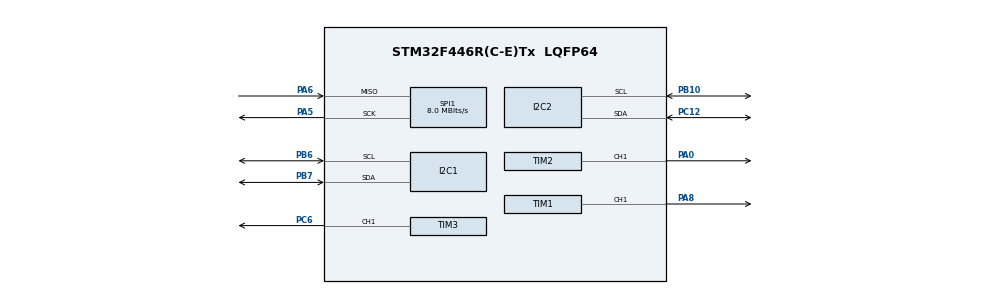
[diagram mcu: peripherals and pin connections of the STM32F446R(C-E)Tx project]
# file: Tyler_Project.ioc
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Mcu.Family=STM32F4
Mcu.Name=STM32F446R(C-E)Tx
Mcu.Package=LQFP64
NVIC.PriorityGroup=NVIC_PRIORITYGROUP_4
PA0-WKUP.Signal=S_TIM2_CH1_ETR
PA5.Mode=RX_Only_Simplex_Unidirect_Master
PA5.Signal=SPI1_SCK
PA6.Mode=RX_Only_Simplex_Unidirect_Master
PA6.Signal=SPI1_MISO
PA8.Signal=S_TIM1_CH1
PB10.Mode=I2C
PB10.Signal=I2C2_SCL
PB6.Mode=I2C
PB6.Signal=I2C1_SCL
PB7.Mode=I2C
PB7.Signal=I2C1_SDA
PC12.Mode=I2C
PC12.Signal=I2C2_SDA
PC6.Signal=S_TIM3_CH1
ProjectManager.HeapSize=0x200
ProjectManager.StackSize=0x400
ProjectManager.TargetToolchain=STM32CubeIDE
RCC.CortexFreq_Value=16000000
RCC.USBFreq_Value=96000000
RCC.VCOOutputFreq_Value=192000000
SH.S_TIM1_CH1.0=TIM1_CH1,PWM Generation1 CH1
SH.S_TIM2_CH1_ETR.0=TIM2_CH1,PWM Generation1 CH1
SH.S_TIM3_CH1.0=TIM3_CH1,PWM Generation1 CH1
SPI1.CalculateBaudRate=8.0 MBits/s
SPI1.Direction=SPI_DIRECTION_2LINES_RXONLY
SPI1.Mode=SPI_MODE_MASTER
SPI1.VirtualType=VM_MASTER
TIM1.Channel-PWM\ Generation1\ CH1=TIM_CHANNEL_1
TIM1.Period=19999
TIM1.Prescaler=15
TIM2.Channel-PWM\ Generation1\ CH1=TIM_CHANNEL_1
TIM2.Period=19999
TIM2.Prescaler=15
TIM3.Channel-PWM\ Generation1\ CH1=TIM_CHANNEL_1
TIM3.Period=19999
TIM3.Prescaler=15
board=custom

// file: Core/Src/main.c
/* USER CODE BEGIN Header */
/**
  ******************************************************************************
  * @file           : main.c
  * @brief          : Main program body
  ******************************************************************************
  * @attention
  *
  * Copyright (c) 2025 STMicroelectronics.
  * All rights reserved.
  *
  * This software is licensed under terms that can be found in the LICENSE file
  * in the root directory of this software component.
  * If no LICENSE file comes with this software, it is provided AS-IS.
  *
  ******************************************************************************
  */
/* USER CODE END Header */
#include "main.h"
#include "stm32f4xx_hal.h"
//#include "vl53l0x_api.h"

I2C_HandleTypeDef hi2c1;
I2C_HandleTypeDef hi2c2;

SPI_HandleTypeDef hspi1;

TIM_HandleTypeDef htim1;
TIM_HandleTypeDef htim2;
TIM_HandleTypeDef htim3;

void SystemClock_Config(void);
static void MX_GPIO_Init(void);
static void MX_I2C1_Init(void);
static void MX_I2C2_Init(void);
static void MX_SPI1_Init(void);
static void MX_TIM1_Init(void);
static void MX_TIM2_Init(void);
static void MX_TIM3_Init(void);

/* USER CODE BEGIN 0 */
void set_pwm_percent(TIM_HandleTypeDef *htim, uint32_t channel, float duty_0_to_1)
{
    if (duty_0_to_1 < 0.0f) duty_0_to_1 = 0.0f;
    if (duty_0_to_1 > 1.0f) duty_0_to_1 = 1.0f;

    uint32_t arr = __HAL_TIM_GET_AUTORELOAD(htim);
    uint32_t ccr = (uint32_t)(duty_0_to_1 * arr);

    __HAL_TIM_SET_COMPARE(htim, channel, ccr);
}

void set_pwm_us(TIM_HandleTypeDef *htim, uint32_t channel, uint16_t us)
{
    uint32_t arr = __HAL_TIM_GET_AUTORELOAD(htim);
    if (us > arr) us = arr;
    __HAL_TIM_SET_COMPARE(htim, channel, us);
}

//uint16_t TOF_GetDistance_mm(void)
//{
//    VL53L0X_Error stat;
//    VL53L0X_RangingMeasurementData_t measure;
//
//    stat = VL53L0X_PerformSingleRangingMeasurement(pDev, &measure);
//    if (stat != VL53L0X_ERROR_NONE) {
//        return 0;
//    }
//    if (measurement.RangeStatus == 0) {
//        return measurement.RangeMilliMeter;
//    } else {
//        return 0;
//    }
//}

/* USER CODE END 0 */

int main(void)
{

  /* MCU Configuration--------------------------------------------------------*/

  /* Reset of all peripherals, Initializes the Flash interface and the Systick. */
  HAL_Init();

  /* Configure the system clock */
  SystemClock_Config();

  /* Initialize all configured peripherals */
  MX_GPIO_Init();
  MX_I2C1_Init();
  MX_I2C2_Init();
  MX_SPI1_Init();
  MX_TIM1_Init();
  MX_TIM2_Init();
  MX_TIM3_Init();
  /* USER CODE BEGIN 2 */
  HAL_TIM_PWM_Start(&htim1, TIM_CHANNEL_1);   // Motor 1
  HAL_TIM_PWM_Start(&htim2, TIM_CHANNEL_1);   // Motor 2
  HAL_TIM_PWM_Start(&htim3, TIM_CHANNEL_1);   // Motor 3

//  pDev->I2cHandle = &hi2c1;
//  pDev->I2cDevAddr = 0x52 >> 1;
//  VL53L0X_Error status = VL53L0X_ERROR_NONE;
//
//  status = VL53L0X_DataInit(pDev);
//  if (status != VL53L0X_ERROR_NONE) {
//      Error_Handler();
//  }
//
//  status = VL53L0X_StaticInit(pDev);
//  if (status != VL53L0X_ERROR_NONE) {
//      Error_Handler();
//  }

  //set_pwm_percent(&htim1, TIM_CHANNEL_1, 0.5); // 50% duty
  //set_pwm_percent(&htim2, TIM_CHANNEL_1, 0.5);
  //set_pwm_percent(&htim3, TIM_CHANNEL_1, 0.5);
  /* USER CODE END 2 */

  /* Infinite loop */
  while (1)
  {
	  //uint16_t depth_mm = TOF_GetDistance_mm();
	  for (uint16_t us = 1000; us <= 2000; us += 20) {
		  set_pwm_us(&htim1, TIM_CHANNEL_1, us);
	      set_pwm_us(&htim2, TIM_CHANNEL_1, us - 1000);
	      set_pwm_us(&htim3, TIM_CHANNEL_1, us - 1000);
	      HAL_Delay(20);
	  }
	  for (uint16_t us = 2000; us >= 1000; us -= 20) {
		  set_pwm_us(&htim1, TIM_CHANNEL_1, us);
	      set_pwm_us(&htim2, TIM_CHANNEL_1, us - 1000);
	      set_pwm_us(&htim3, TIM_CHANNEL_1, us - 1000);
	      HAL_Delay(20);
	  }
  }
}

void SystemClock_Config(void)
{
  RCC_OscInitTypeDef RCC_OscInitStruct = {0};
  RCC_ClkInitTypeDef RCC_ClkInitStruct = {0};

  /** Configure the main internal regulator output voltage
  */
  __HAL_RCC_PWR_CLK_ENABLE();
  __HAL_PWR_VOLTAGESCALING_CONFIG(PWR_REGULATOR_VOLTAGE_SCALE3);

  /** Initializes the RCC Oscillators according to the specified parameters
  * in the RCC_OscInitTypeDef structure.
  */
  RCC_OscInitStruct.OscillatorType = RCC_OSCILLATORTYPE_HSI;
  RCC_OscInitStruct.HSIState = RCC_HSI_ON;
  RCC_OscInitStruct.HSICalibrationValue = RCC_HSICALIBRATION_DEFAULT;
  RCC_OscInitStruct.PLL.PLLState = RCC_PLL_NONE;
  if (HAL_RCC_OscConfig(&RCC_OscInitStruct) != HAL_OK)
  {
    Error_Handler();
  }

  /** Initializes the CPU, AHB and APB buses clocks
  */
  RCC_ClkInitStruct.ClockType = RCC_CLOCKTYPE_HCLK|RCC_CLOCKTYPE_SYSCLK
                              |RCC_CLOCKTYPE_PCLK1|RCC_CLOCKTYPE_PCLK2;
  RCC_ClkInitStruct.SYSCLKSource = RCC_SYSCLKSOURCE_HSI;
  RCC_ClkInitStruct.AHBCLKDivider = RCC_SYSCLK_DIV1;
  RCC_ClkInitStruct.APB1CLKDivider = RCC_HCLK_DIV1;
  RCC_ClkInitStruct.APB2CLKDivider = RCC_HCLK_DIV1;

  if (HAL_RCC_ClockConfig(&RCC_ClkInitStruct, FLASH_LATENCY_0) != HAL_OK)
  {
    Error_Handler();
  }
}

static void MX_I2C1_Init(void)
{

  hi2c1.Instance = I2C1;
  hi2c1.Init.ClockSpeed = 100000;
  hi2c1.Init.DutyCycle = I2C_DUTYCYCLE_2;
  hi2c1.Init.OwnAddress1 = 0;
  hi2c1.Init.AddressingMode = I2C_ADDRESSINGMODE_7BIT;
  hi2c1.Init.DualAddressMode = I2C_DUALADDRESS_DISABLE;
  hi2c1.Init.OwnAddress2 = 0;
  hi2c1.Init.GeneralCallMode = I2C_GENERALCALL_DISABLE;
  hi2c1.Init.NoStretchMode = I2C_NOSTRETCH_DISABLE;
  if (HAL_I2C_Init(&hi2c1) != HAL_OK)
  {
    Error_Handler();
  }

}

static void MX_I2C2_Init(void)
{

  hi2c2.Instance = I2C2;
  hi2c2.Init.ClockSpeed = 100000;
  hi2c2.Init.DutyCycle = I2C_DUTYCYCLE_2;
  hi2c2.Init.OwnAddress1 = 0;
  hi2c2.Init.AddressingMode = I2C_ADDRESSINGMODE_7BIT;
  hi2c2.Init.DualAddressMode = I2C_DUALADDRESS_DISABLE;
  hi2c2.Init.OwnAddress2 = 0;
  hi2c2.Init.GeneralCallMode = I2C_GENERALCALL_DISABLE;
  hi2c2.Init.NoStretchMode = I2C_NOSTRETCH_DISABLE;
  if (HAL_I2C_Init(&hi2c2) != HAL_OK)
  {
    Error_Handler();
  }

}

static void MX_SPI1_Init(void)
{

  /* SPI1 parameter configuration*/
  hspi1.Instance = SPI1;
  hspi1.Init.Mode = SPI_MODE_MASTER;
  hspi1.Init.Direction = SPI_DIRECTION_2LINES_RXONLY;
  hspi1.Init.DataSize = SPI_DATASIZE_8BIT;
  hspi1.Init.CLKPolarity = SPI_POLARITY_LOW;
  hspi1.Init.CLKPhase = SPI_PHASE_1EDGE;
  hspi1.Init.NSS = SPI_NSS_SOFT;
  hspi1.Init.BaudRatePrescaler = SPI_BAUDRATEPRESCALER_2;
  hspi1.Init.FirstBit = SPI_FIRSTBIT_MSB;
  hspi1.Init.TIMode = SPI_TIMODE_DISABLE;
  hspi1.Init.CRCCalculation = SPI_CRCCALCULATION_DISABLE;
  hspi1.Init.CRCPolynomial = 10;
  if (HAL_SPI_Init(&hspi1) != HAL_OK)
  {
    Error_Handler();
  }

}

static void MX_TIM1_Init(void)
{

  TIM_MasterConfigTypeDef sMasterConfig = {0};
  TIM_OC_InitTypeDef sConfigOC = {0};
  TIM_BreakDeadTimeConfigTypeDef sBreakDeadTimeConfig = {0};

  htim1.Instance = TIM1;
  htim1.Init.Prescaler = 15;
  htim1.Init.CounterMode = TIM_COUNTERMODE_UP;
  htim1.Init.Period = 19999;
  htim1.Init.ClockDivision = TIM_CLOCKDIVISION_DIV1;
  htim1.Init.RepetitionCounter = 0;
  htim1.Init.AutoReloadPreload = TIM_AUTORELOAD_PRELOAD_DISABLE;
  if (HAL_TIM_PWM_Init(&htim1) != HAL_OK)
  {
    Error_Handler();
  }
  sMasterConfig.MasterOutputTrigger = TIM_TRGO_RESET;
  sMasterConfig.MasterSlaveMode = TIM_MASTERSLAVEMODE_DISABLE;
  if (HAL_TIMEx_MasterConfigSynchronization(&htim1, &sMasterConfig) != HAL_OK)
  {
    Error_Handler();
  }
  sConfigOC.OCMode = TIM_OCMODE_PWM1;
  sConfigOC.Pulse = 0;
  sConfigOC.OCPolarity = TIM_OCPOLARITY_HIGH;
  sConfigOC.OCNPolarity = TIM_OCNPOLARITY_HIGH;
  sConfigOC.OCFastMode = TIM_OCFAST_DISABLE;
  sConfigOC.OCIdleState = TIM_OCIDLESTATE_RESET;
  sConfigOC.OCNIdleState = TIM_OCNIDLESTATE_RESET;
  if (HAL_TIM_PWM_ConfigChannel(&htim1, &sConfigOC, TIM_CHANNEL_1) != HAL_OK)
  {
    Error_Handler();
  }
  sBreakDeadTimeConfig.OffStateRunMode = TIM_OSSR_DISABLE;
  sBreakDeadTimeConfig.OffStateIDLEMode = TIM_OSSI_DISABLE;
  sBreakDeadTimeConfig.LockLevel = TIM_LOCKLEVEL_OFF;
  sBreakDeadTimeConfig.DeadTime = 0;
  sBreakDeadTimeConfig.BreakState = TIM_BREAK_DISABLE;
  sBreakDeadTimeConfig.BreakPolarity = TIM_BREAKPOLARITY_HIGH;
  sBreakDeadTimeConfig.AutomaticOutput = TIM_AUTOMATICOUTPUT_DISABLE;
  if (HAL_TIMEx_ConfigBreakDeadTime(&htim1, &sBreakDeadTimeConfig) != HAL_OK)
  {
    Error_Handler();
  }
  HAL_TIM_MspPostInit(&htim1);

}

static void MX_TIM2_Init(void)
{

  TIM_MasterConfigTypeDef sMasterConfig = {0};
  TIM_OC_InitTypeDef sConfigOC = {0};

  htim2.Instance = TIM2;
  htim2.Init.Prescaler = 15;
  htim2.Init.CounterMode = TIM_COUNTERMODE_UP;
  htim2.Init.Period = 19999;
  htim2.Init.ClockDivision = TIM_CLOCKDIVISION_DIV1;
  htim2.Init.AutoReloadPreload = TIM_AUTORELOAD_PRELOAD_DISABLE;
  if (HAL_TIM_PWM_Init(&htim2) != HAL_OK)
  {
    Error_Handler();
  }
  sMasterConfig.MasterOutputTrigger = TIM_TRGO_RESET;
  sMasterConfig.MasterSlaveMode = TIM_MASTERSLAVEMODE_DISABLE;
  if (HAL_TIMEx_MasterConfigSynchronization(&htim2, &sMasterConfig) != HAL_OK)
  {
    Error_Handler();
  }
  sConfigOC.OCMode = TIM_OCMODE_PWM1;
  sConfigOC.Pulse = 0;
  sConfigOC.OCPolarity = TIM_OCPOLARITY_HIGH;
  sConfigOC.OCFastMode = TIM_OCFAST_DISABLE;
  if (HAL_TIM_PWM_ConfigChannel(&htim2, &sConfigOC, TIM_CHANNEL_1) != HAL_OK)
  {
    Error_Handler();
  }
  HAL_TIM_MspPostInit(&htim2);

}

static void MX_TIM3_Init(void)
{

  TIM_MasterConfigTypeDef sMasterConfig = {0};
  TIM_OC_InitTypeDef sConfigOC = {0};

  htim3.Instance = TIM3;
  htim3.Init.Prescaler = 15;
  htim3.Init.CounterMode = TIM_COUNTERMODE_UP;
  htim3.Init.Period = 19999;
  htim3.Init.ClockDivision = TIM_CLOCKDIVISION_DIV1;
  htim3.Init.AutoReloadPreload = TIM_AUTORELOAD_PRELOAD_DISABLE;
  if (HAL_TIM_PWM_Init(&htim3) != HAL_OK)
  {
    Error_Handler();
  }
  sMasterConfig.MasterOutputTrigger = TIM_TRGO_RESET;
  sMasterConfig.MasterSlaveMode = TIM_MASTERSLAVEMODE_DISABLE;
  if (HAL_TIMEx_MasterConfigSynchronization(&htim3, &sMasterConfig) != HAL_OK)
  {
    Error_Handler();
  }
  sConfigOC.OCMode = TIM_OCMODE_PWM1;
  sConfigOC.Pulse = 0;
  sConfigOC.OCPolarity = TIM_OCPOLARITY_HIGH;
  sConfigOC.OCFastMode = TIM_OCFAST_DISABLE;
  if (HAL_TIM_PWM_ConfigChannel(&htim3, &sConfigOC, TIM_CHANNEL_1) != HAL_OK)
  {
    Error_Handler();
  }
  HAL_TIM_MspPostInit(&htim3);

}

static void MX_GPIO_Init(void)
{

  /* GPIO Ports Clock Enable */
  __HAL_RCC_GPIOA_CLK_ENABLE();
  __HAL_RCC_GPIOB_CLK_ENABLE();
  __HAL_RCC_GPIOC_CLK_ENABLE();

}

void Error_Handler(void)
{
  __disable_irq();
  while (1)
  {
  }
}
